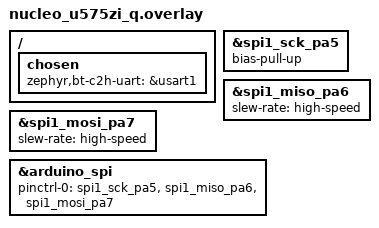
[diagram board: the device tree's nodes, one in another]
/*
 * Copyright (c) 2024 STMicroelectronics
 *
 * SPDX-License-Identifier: Apache-2.0
 */

&spi1_sck_pa5 {
	/delete-property/ bias-pull-down;
	bias-pull-up;
};

&spi1_miso_pa6 {
	slew-rate = "high-speed";
};

&spi1_mosi_pa7 {
	slew-rate = "high-speed";
};

&arduino_spi {
	pinctrl-0 = <&spi1_sck_pa5 &spi1_miso_pa6 &spi1_mosi_pa7>;
};

/ {
	chosen {
		zephyr,bt-c2h-uart = &usart1;
	};
};
